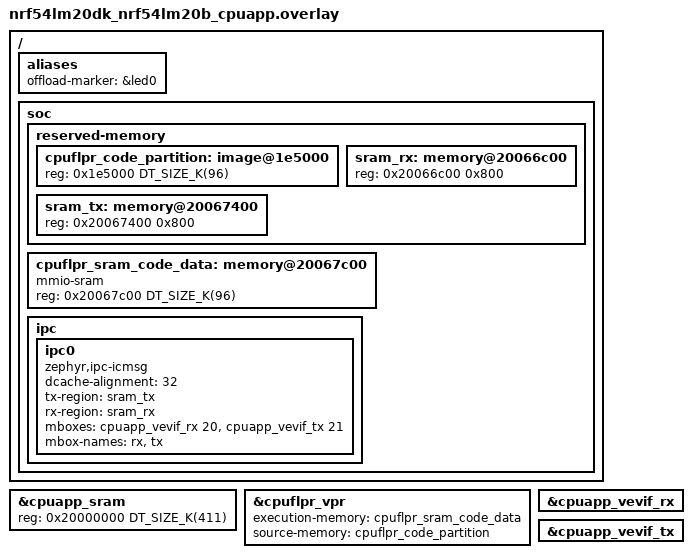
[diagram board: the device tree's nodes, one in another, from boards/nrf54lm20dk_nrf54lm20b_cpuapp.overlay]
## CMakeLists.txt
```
#
# Copyright (c) 2026 Nordic Semiconductor ASA
#
# SPDX-License-Identifier: LicenseRef-Nordic-5-Clause
#

cmake_minimum_required(VERSION 3.20.0)

find_package(Zephyr REQUIRED HINTS $ENV{ZEPHYR_BASE})
project(flpr_offload)

# app_transmit() is the M33 end of the pipeline in both builds.
target_sources(app PRIVATE src/main.c app/app_transmit.c)
target_include_directories(app PRIVATE common app)

# In the offloaded build the workload (peripheral backend, loop and processing)
# is linked into the FLPR image, and this image only receives its results. In
# the local baseline the same workload sources are linked here instead.
if(CONFIG_APP_OFFLOAD)
  target_sources(app PRIVATE src/offloaded.c)
else()
  target_sources(app PRIVATE src/local.c)
  include(common/workload.cmake)
endif()
```

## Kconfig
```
#
# Copyright (c) 2026 Nordic Semiconductor ASA
#
# SPDX-License-Identifier: LicenseRef-Nordic-5-Clause
#

menu "FLPR offload sample"

config APP_OFFLOAD
	bool "Run the workload on the FLPR"
	default y
	help
	  When enabled the workload and its transport run on the FLPR and the
	  Cortex-M33 only receives results. When disabled the same workload runs
	  on the Cortex-M33 and no FLPR image is built. Use the "local" file
	  suffix to select the disabled configuration from the same source.

config APP_ITERATIONS
	int "Batches to run (0 runs continuously)"
	default 0
	help
	  Number of batches the workload runs before stopping. Zero runs
	  continuously, which is the usual mode for measuring steady-state load
	  and power.

config APP_SAMPLE_INTERVAL_MS
	int "Delay between batches in milliseconds (0 samples continuously)"
	default 100
	help
	  Timer-based sampling cadence: the workload acquires and processes one
	  batch, then waits this long before the next. Zero removes the wait and
	  runs back to back, which is the throughput / compute-bound mode. In the
	  offloaded build the M33 passes this value to the FLPR. The interrupt
	  trigger ignores it: the peripheral sets the rate.

config APP_REPORT_INTERVAL_MS
	int "Measurement report interval in milliseconds"
	default 1000

rsource "common/Kconfig.workload"

endmenu

source "Kconfig.zephyr"
```

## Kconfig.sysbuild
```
#
# Copyright (c) 2026 Nordic Semiconductor ASA
#
# SPDX-License-Identifier: LicenseRef-Nordic-5-Clause
#

config REMOTE_BOARD
	string "The board target used for the FLPR image"
	default "nrf54lm20dk/nrf54lm20b/cpuflpr" if BOARD_NRF54LM20DK_NRF54LM20B_CPUAPP

config PARTITION_MANAGER
	default n

source "share/sysbuild/Kconfig"
```

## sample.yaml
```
sample:
  name: FLPR offload template
  description: >
    Template for moving a workload and its dependencies from the Cortex-M33 to
    the FLPR, with instrumentation to measure the result. Builds either fully on
    the M33 or offloaded to the FLPR from the same source.

common:
  sysbuild: true
  tags:
    - ipc
    - flpr
    - multicore
  harness: console
  harness_config:
    type: multi_line
    ordered: false
    regex:
      - "FLPR offload sample"
      - "M33 active .* \\| (?!0 results)[0-9.]+ results/s"

  platform_allow:
    - nrf54lm20dk/nrf54lm20b/cpuapp
  integration_platforms:
    - nrf54lm20dk/nrf54lm20b/cpuapp

# The SAADC and compute_only run on a bare DK. The accelerometer tests are build-only: they need
# the sensor wired to the DK (pins in each peripherals/<name>/peripheral.overlay).
tests:
  sample.flpr_offload.offloaded:
    extra_args:
      - OFFLOAD_PERIPHERAL=saadc
  sample.flpr_offload.interrupt:
    extra_args:
      - OFFLOAD_PERIPHERAL=saadc
      - OFFLOAD_TRIGGER=interrupt
  sample.flpr_offload.local:
    extra_args:
      - FILE_SUFFIX=local
      - OFFLOAD_PERIPHERAL=saadc
  sample.flpr_offload.local.interrupt:
    extra_args:
      - FILE_SUFFIX=local
      - OFFLOAD_PERIPHERAL=saadc
      - OFFLOAD_TRIGGER=interrupt
  sample.flpr_offload.lis2dh.offloaded:
    build_only: true
    extra_args:
      - OFFLOAD_PERIPHERAL=twim_lis2dh
  sample.flpr_offload.lis2dh.interrupt:
    build_only: true
    extra_args:
      - OFFLOAD_PERIPHERAL=twim_lis2dh
      - OFFLOAD_TRIGGER=interrupt
  sample.flpr_offload.lis2dh.local:
    build_only: true
    extra_args:
      - FILE_SUFFIX=local
      - OFFLOAD_PERIPHERAL=twim_lis2dh
  sample.flpr_offload.lis2dh.local.interrupt:
    build_only: true
    extra_args:
      - FILE_SUFFIX=local
      - OFFLOAD_PERIPHERAL=twim_lis2dh
      - OFFLOAD_TRIGGER=interrupt
  sample.flpr_offload.adxl362.offloaded:
    build_only: true
    extra_args:
      - OFFLOAD_PERIPHERAL=spim_adxl362
  sample.flpr_offload.adxl362.interrupt:
    build_only: true
    extra_args:
      - OFFLOAD_PERIPHERAL=spim_adxl362
      - OFFLOAD_TRIGGER=interrupt
  sample.flpr_offload.adxl362.local:
    build_only: true
    extra_args:
      - FILE_SUFFIX=local
      - OFFLOAD_PERIPHERAL=spim_adxl362
  sample.flpr_offload.adxl362.local.interrupt:
    build_only: true
    extra_args:
      - FILE_SUFFIX=local
      - OFFLOAD_PERIPHERAL=spim_adxl362
      - OFFLOAD_TRIGGER=interrupt
  sample.flpr_offload.compute_only.offloaded:
    extra_args:
      - OFFLOAD_PERIPHERAL=compute_only
  sample.flpr_offload.compute_only.local:
    extra_args:
      - FILE_SUFFIX=local
      - OFFLOAD_PERIPHERAL=compute_only
```

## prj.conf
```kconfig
# Copyright (c) 2026 Nordic Semiconductor ASA
# SPDX-License-Identifier: LicenseRef-Nordic-5-Clause

# Offloaded configuration: the workload runs on the FLPR, this image receives
# results over the inter-core transport.
CONFIG_APP_OFFLOAD=y

CONFIG_LOG=y
CONFIG_GPIO=y

# Inter-core transport (ICMsg over the shared-memory region in the overlay).
CONFIG_IPC_SERVICE=y
CONFIG_MBOX=y
CONFIG_HEAP_MEM_POOL_SIZE=4096

# M33 active and idle time. SCHED_THREAD_USAGE_ALL adds the per-CPU idle count.
CONFIG_THREAD_RUNTIME_STATS=y
CONFIG_SCHED_THREAD_USAGE_ALL=y
```

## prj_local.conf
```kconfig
# Copyright (c) 2026 Nordic Semiconductor ASA
# SPDX-License-Identifier: LicenseRef-Nordic-5-Clause

# Local baseline: the same workload runs on the Cortex-M33. No FLPR image and no
# inter-core transport are built, so this image is the comparison point for the
# offloaded configuration.
CONFIG_APP_OFFLOAD=n

CONFIG_LOG=y
CONFIG_GPIO=y

# In the local build the workload and its peripheral driver run here, on the
# M33. sysbuild.cmake adds the driver Kconfig from peripherals/<name>/.

# M33 active and idle time. SCHED_THREAD_USAGE_ALL adds the per-CPU idle count.
CONFIG_THREAD_RUNTIME_STATS=y
CONFIG_SCHED_THREAD_USAGE_ALL=y
```

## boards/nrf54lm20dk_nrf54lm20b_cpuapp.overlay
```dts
/*
 * Copyright (c) 2026 Nordic Semiconductor ASA
 *
 * SPDX-License-Identifier: LicenseRef-Nordic-5-Clause
 */

/*
 * M33 side of the offloaded build. This overlay does two things:
 *   1. Launches the FLPR: it points the VPR launcher at the FLPR code partition
 *      in RRAM (source) and the FLPR execution SRAM (destination), and shrinks
 *      the application SRAM so the top 96 KB belongs to the FLPR and the 4 KB
 *      below it to the IPC.
 *   2. Sets up the ICMsg transport: two small shared-memory regions plus the
 *      vevif mailboxes that signal the other core.
 *
 * The FLPR execution region is the top 96 KB of SRAM. On this DK that is the
 * default FLPR carve. The two IPC regions sit directly below it, still reachable
 * by both cores.
 *
 * Nothing here depends on the peripheral. sysbuild.cmake adds
 * peripherals/<name>/hand_to_flpr.overlay, which hands that peripheral over.
 */

/ {
	aliases {
		offload-marker = &led0;
	};

	soc {
		reserved-memory {
			#address-cells = <1>;
			#size-cells = <1>;

			cpuflpr_code_partition: image@1e5000 {
				reg = <0x1e5000 DT_SIZE_K(96)>;
			};

			sram_rx: memory@20066c00 {
				reg = <0x20066c00 0x800>;
			};

			sram_tx: memory@20067400 {
				reg = <0x20067400 0x800>;
			};
		};

		cpuflpr_sram_code_data: memory@20067c00 {
			compatible = "mmio-sram";
			reg = <0x20067c00 DT_SIZE_K(96)>;
			#address-cells = <1>;
			#size-cells = <1>;
			ranges = <0x0 0x20067c00 DT_SIZE_K(96)>;
		};

		ipc {
			ipc0: ipc0 {
				compatible = "zephyr,ipc-icmsg";
				dcache-alignment = <32>;
				tx-region = <&sram_tx>;
				rx-region = <&sram_rx>;
				mboxes = <&cpuapp_vevif_rx 20>, <&cpuapp_vevif_tx 21>;
				mbox-names = "rx", "tx";
				status = "okay";
			};
		};
	};
};

/* M33 RAM ends where the IPC regions start, so it never overlaps them. */
&cpuapp_sram {
	reg = <0x20000000 DT_SIZE_K(411)>;
	ranges = <0x0 0x20000000 DT_SIZE_K(411)>;
};

&cpuflpr_vpr {
	status = "okay";
	execution-memory = <&cpuflpr_sram_code_data>;
	source-memory = <&cpuflpr_code_partition>;
};

&cpuapp_vevif_rx {
	status = "okay";
};

&cpuapp_vevif_tx {
	status = "okay";
};
```

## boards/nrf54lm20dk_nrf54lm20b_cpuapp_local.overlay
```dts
/*
 * Copyright (c) 2026 Nordic Semiconductor ASA
 *
 * SPDX-License-Identifier: LicenseRef-Nordic-5-Clause
 */

/*
 * Local baseline. The workload runs on the M33, so there is no FLPR launch and
 * no inter-core transport: the SRAM stays whole. sysbuild.cmake adds
 * peripherals/<name>/peripheral.overlay to this image, the same overlay the FLPR
 * gets in the offloaded build, so both cores drive an identical peripheral setup.
 */

/ {
	aliases {
		offload-marker = &led0;
	};
};
```

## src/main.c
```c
/*
 * Copyright (c) 2026 Nordic Semiconductor ASA
 *
 * SPDX-License-Identifier: LicenseRef-Nordic-5-Clause
 */

/*
 * M33 entry point and the measurement report. Nothing here changes with the
 * peripheral or the processing; your M33 code is app/app_transmit.c.
 */

#include <zephyr/kernel.h>
#include <zephyr/logging/log.h>
#include <zephyr/sys/atomic.h>

#include "app_metrics.h"
#include "host.h"

LOG_MODULE_REGISTER(host, LOG_LEVEL_INF);

#define WORKLOAD_CORE (IS_ENABLED(CONFIG_APP_OFFLOAD) ? "FLPR" : "M33")

/* Written per result by report_batch(), read once per interval by report_print(). */
static atomic_t results;
static atomic_t acquire_sum_us;
static atomic_t process_sum_us;

static struct cpu_load load;
static int64_t prev_ms;
static uint32_t prev_results;
static uint32_t prev_acquire_us;
static uint32_t prev_process_us;

void report_start(void)
{
	(void)cpu_load_active_permille(&load);
	prev_ms = k_uptime_get();
}

void report_batch(uint32_t acquire_us, uint32_t process_us)
{
	atomic_add(&acquire_sum_us, (atomic_val_t)acquire_us);
	atomic_add(&process_sum_us, (atomic_val_t)process_us);
	atomic_inc(&results);
}

/*
 * One line per interval: the M33 load, the result rate, and the average time the
 * workload core spent acquiring and processing one batch. Unsigned differences
 * keep the counters correct across wraparound.
 */
void report_print(void)
{
	int64_t now = k_uptime_get();
	uint32_t dt_ms = (uint32_t)(now - prev_ms);
	uint32_t n = (uint32_t)atomic_get(&results);
	uint32_t acq = (uint32_t)atomic_get(&acquire_sum_us);
	uint32_t proc = (uint32_t)atomic_get(&process_sum_us);
	uint32_t d_n = n - prev_results;
	uint32_t d_acq = acq - prev_acquire_us;
	uint32_t d_proc = proc - prev_process_us;
	uint32_t active = cpu_load_active_permille(&load);
	uint32_t rate10 = dt_ms ? (uint32_t)((uint64_t)d_n * 10000U / dt_ms) : 0;

	prev_ms = now;
	prev_results = n;
	prev_acquire_us = acq;
	prev_process_us = proc;

	if (d_n == 0) {
		LOG_INF("M33 active %u.%u%% | 0 results/s", active / 10, active % 10);
		return;
	}

	uint32_t acq10 = (uint32_t)((uint64_t)d_acq * 10U / d_n);
	uint32_t proc10 = (uint32_t)((uint64_t)d_proc * 10U / d_n);

	LOG_INF("M33 active %u.%u%% | %u.%u results/s | %s per batch: acquire %u.%u us, "
		"process %u.%u us",
		active / 10, active % 10, rate10 / 10, rate10 % 10, WORKLOAD_CORE,
		acq10 / 10, acq10 % 10, proc10 / 10, proc10 % 10);
}

int main(void)
{
	LOG_INF("FLPR offload sample: workload on %s, peripheral %s, %s trigger",
		WORKLOAD_CORE, CONFIG_APP_PERIPHERAL,
		IS_ENABLED(CONFIG_APP_TRIGGER_INTERRUPT) ? "interrupt" : "timer");
	marker_init();

	return host_run();
}
```

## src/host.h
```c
/*
 * Copyright (c) 2026 Nordic Semiconductor ASA
 *
 * SPDX-License-Identifier: LicenseRef-Nordic-5-Clause
 */

#ifndef HOST_H_
#define HOST_H_

#include <stdint.h>

/*
 * The M33 host. main.c prints the report; one of two files runs the workload:
 * offloaded.c (the FLPR runs it, the M33 receives the results) or local.c (the
 * M33 runs it itself, the baseline). CONFIG_APP_OFFLOAD picks the file.
 */

/* Runs the whole sample. Returns when the run ends or fails. */
int host_run(void);

/* The once-per-interval report line, implemented in main.c. */
void report_start(void);
void report_batch(uint32_t acquire_us, uint32_t process_us);
void report_print(void);

#endif /* HOST_H_ */
```

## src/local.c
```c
/*
 * Copyright (c) 2026 Nordic Semiconductor ASA
 *
 * SPDX-License-Identifier: LicenseRef-Nordic-5-Clause
 */

/*
 * Baseline build: the M33 runs the same workload itself, from the same source
 * the FLPR runs in the offloaded build. Compare its report line with the
 * offloaded one.
 *
 * The workload runs in its own thread at the lowest application priority, the
 * priority of the log thread, so that even back to back (interval 0) it shares
 * the CPU with logging through time slicing. The report runs in main, which
 * preempts it once per interval.
 */

#include <zephyr/kernel.h>
#include <zephyr/logging/log.h>

#include "host.h"
#include "workload.h"
#include "workload_loop.h"

LOG_MODULE_DECLARE(host);

#define WORKLOAD_STACK_SIZE 2048

static K_THREAD_STACK_DEFINE(workload_stack, WORKLOAD_STACK_SIZE);
static struct k_thread workload_thread;
static int workload_ret;

static int emit(uint32_t seq, const void *result, size_t len, uint32_t acquire_us,
		uint32_t process_us)
{
	report_batch(acquire_us, process_us);
	app_transmit(seq, result, len);
	return 0;
}

static void workload_entry(void *p1, void *p2, void *p3)
{
	ARG_UNUSED(p1);
	ARG_UNUSED(p2);
	ARG_UNUSED(p3);

	workload_ret = workload_loop(CONFIG_APP_ITERATIONS, CONFIG_APP_SAMPLE_INTERVAL_MS, emit);
}

int host_run(void)
{
	int ret = workload_init();

	if (ret < 0) {
		LOG_ERR("workload_init failed (%d)", ret);
		return ret;
	}

	report_start();
	k_thread_create(&workload_thread, workload_stack, K_THREAD_STACK_SIZEOF(workload_stack),
			workload_entry, NULL, NULL, NULL, K_LOWEST_APPLICATION_THREAD_PRIO, 0,
			K_NO_WAIT);
	k_thread_name_set(&workload_thread, "workload");

	/* Print the report every interval until the workload thread ends. */
	while (k_thread_join(&workload_thread, K_MSEC(CONFIG_APP_REPORT_INTERVAL_MS)) != 0) {
		report_print();
	}

	if (workload_ret < 0) {
		LOG_ERR("workload stopped (%d)", workload_ret);
		return workload_ret;
	}

	LOG_INF("run complete");
	return 0;
}
```

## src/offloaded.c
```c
/*
 * Copyright (c) 2026 Nordic Semiconductor ASA
 *
 * SPDX-License-Identifier: LicenseRef-Nordic-5-Clause
 */

/*
 * Offloaded build: the FLPR runs the workload and the M33 only forwards.
 *
 * The M33 starts the FLPR with one control message. After that each result
 * arrives over IPC and is handed to app_transmit() from this thread. The IPC
 * receive callback runs in the IPC service work queue, which must not block, so
 * it only copies the message into a queue.
 */

#include <zephyr/kernel.h>
#include <zephyr/ipc/ipc_service.h>
#include <zephyr/logging/log.h>
#include <zephyr/sys/atomic.h>
#include <zephyr/sys/util.h>

#include "host.h"
#include "offload_protocol.h"
#include "workload.h"

LOG_MODULE_DECLARE(host);

/* Results waiting for app_transmit(). When it falls this far behind, results are dropped. */
#define RESULT_QUEUE_DEPTH 8

static const struct device *const ipc0 = DEVICE_DT_GET(DT_NODELABEL(ipc0));
static struct ipc_ept ep;
static K_SEM_DEFINE(bound_sem, 0, 1);
K_MSGQ_DEFINE(result_q, sizeof(struct offload_msg), RESULT_QUEUE_DEPTH, 4);

static atomic_t dropped;
static atomic_t run_ended;
static atomic_t run_error;

static void ep_bound(void *priv)
{
	ARG_UNUSED(priv);
	k_sem_give(&bound_sem);
}

/* IPC service work queue: copy and return. */
static void ep_recv(const void *data, size_t len, void *priv)
{
	const struct offload_msg *msg = data;

	ARG_UNUSED(priv);

	if (len != sizeof(*msg)) {
		LOG_WRN_ONCE("unexpected message size %u, are both images from the same build?",
			     (uint32_t)len);
		return;
	}

	switch (msg->type) {
	case OFFLOAD_MSG_RESULT:
		if (k_msgq_put(&result_q, msg, K_NO_WAIT) < 0) {
			atomic_inc(&dropped);
		}
		break;
	case OFFLOAD_MSG_STATUS:
		if (msg->status == OFFLOAD_STATUS_DONE) {
			atomic_set(&run_ended, 1);
		}
		break;
	case OFFLOAD_MSG_ERROR:
		atomic_set(&run_error, msg->error);
		atomic_set(&run_ended, 1);
		break;
	default:
		break;
	}
}

static int send_control(void)
{
	const struct offload_msg msg = {
		.type = OFFLOAD_MSG_CONTROL,
		.control = {
			.iterations = CONFIG_APP_ITERATIONS,
			.sample_interval_ms = CONFIG_APP_SAMPLE_INTERVAL_MS,
		},
	};

	/* -ENOMEM means the shared buffer is momentarily full; try again shortly. */
	for (int try = 0; try < 100; try++) {
		int ret = ipc_service_send(&ep, &msg, sizeof(msg));

		if (ret >= 0) {
			return 0;
		}
		if (ret != -ENOMEM) {
			return ret;
		}
		k_msleep(1);
	}

	return -ETIMEDOUT;
}

static void forward(const struct offload_msg *msg)
{
	const struct offload_result *res = &msg->result;

	report_batch(res->acquire_us, res->process_us);
	app_transmit(res->iteration, res->bytes, MIN(res->len, sizeof(res->bytes)));
}

int host_run(void)
{
	static struct ipc_ept_cfg ep_cfg = {
		.name = "offload",
		.cb = {
			.bound = ep_bound,
			.received = ep_recv,
		},
	};
	struct offload_msg msg;
	uint32_t prev_dropped = 0;
	int64_t next_report;
	int ret;

	ret = ipc_service_open_instance(ipc0);
	if (ret < 0 && ret != -EALREADY) {
		LOG_ERR("ipc_service_open_instance failed (%d)", ret);
		return ret;
	}

	ret = ipc_service_register_endpoint(ipc0, &ep, &ep_cfg);
	if (ret < 0) {
		LOG_ERR("ipc_service_register_endpoint failed (%d)", ret);
		return ret;
	}

	while (k_sem_take(&bound_sem, K_SECONDS(5)) != 0) {
		LOG_WRN("no answer from the FLPR yet: was the FLPR image flashed? "
			"(west flash from the build directory flashes both)");
	}

	ret = send_control();
	if (ret < 0) {
		LOG_ERR("failed to start the FLPR (%d)", ret);
		return ret;
	}
	LOG_INF("FLPR started");

	report_start();
	next_report = k_uptime_get() + CONFIG_APP_REPORT_INTERVAL_MS;

	while (!atomic_get(&run_ended)) {
		int64_t wait_ms = MAX(next_report - k_uptime_get(), 0);

		if (k_msgq_get(&result_q, &msg, K_MSEC(wait_ms)) == 0) {
			forward(&msg);
		}

		if (k_uptime_get() >= next_report) {
			uint32_t d = (uint32_t)atomic_get(&dropped);

			report_print();
			if (d != prev_dropped) {
				LOG_WRN("%u results dropped: app_transmit() is slower than the FLPR",
					d - prev_dropped);
				prev_dropped = d;
			}
			/* From now, not from the last deadline: a long app_transmit() must not
			 * cause a burst of reports.
			 */
			next_report = k_uptime_get() + CONFIG_APP_REPORT_INTERVAL_MS;
		}
	}

	/* The FLPR sends its last results before DONE or ERROR, so they are queued. */
	while (k_msgq_get(&result_q, &msg, K_NO_WAIT) == 0) {
		forward(&msg);
	}

	ret = (int)atomic_get(&run_error);
	if (ret < 0) {
		LOG_ERR("the FLPR stopped the workload with error %d; its own log is on the "
			"FLPR console (uart30)", ret);
		return ret;
	}

	LOG_INF("run complete");
	return 0;
}
```
